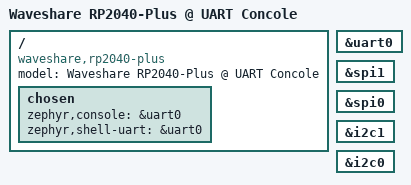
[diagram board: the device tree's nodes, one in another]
/*
 * Copyright (c) 2023-2025 TiaC Systems
 * SPDX-License-Identifier: Apache-2.0
 */

/dts-v1/;

/ {
	model = "Waveshare RP2040-Plus @ UART Concole";
	compatible = "waveshare,rp2040-plus", "waveshare,rp2040-plus-uartcons";

	chosen {
		zephyr,console = &uart0;
		zephyr,shell-uart = &uart0;
	};
};

#include "waveshare_rp2040-pico.dtsi"

#include "rpipico_led.dtsi"
#include "rpipico_connector.dtsi"
#include "rpipico_r3_connector.dtsi"

rpipico_serial: &uart0 {};
rpipico_spi1: &spi1 {};
rpipico_spi0: &spi0 {};
rpipico_spi: &rpipico_spi0 {};
rpipico_i2c1: &i2c1 {};
rpipico_i2c0: &i2c0 {};
rpipico_i2c: &rpipico_i2c0 {};

pico_serial: &rpipico_serial {};
pico_spi1: &rpipico_spi1 {};
pico_spi0: &rpipico_spi0 {};
pico_spi: &pico_spi0 {};
pico_i2c1: &rpipico_i2c1 {};
pico_i2c0: &rpipico_i2c0 {};
pico_i2c: &pico_i2c0 {};
